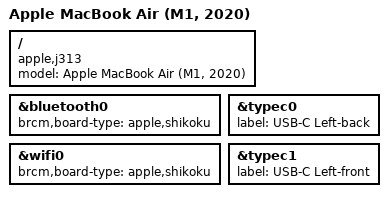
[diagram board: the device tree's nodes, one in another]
// SPDX-License-Identifier: GPL-2.0+ OR MIT
/*
 * Apple MacBook Air (M1, 2020)
 *
 * target-type: J313
 *
 * Copyright The Asahi Linux Contributors
 */

/dts-v1/;

#include "t8103.dtsi"
#include "t8103-jxxx.dtsi"

/ {
	compatible = "apple,j313", "apple,t8103", "apple,arm-platform";
	model = "Apple MacBook Air (M1, 2020)";
};

&bluetooth0 {
	brcm,board-type = "apple,shikoku";
};

&wifi0 {
	brcm,board-type = "apple,shikoku";
};

/*
 * Provide labels for the USB type C ports.
 */

&typec0 {
	label = "USB-C Left-back";
};

&typec1 {
	label = "USB-C Left-front";
};
